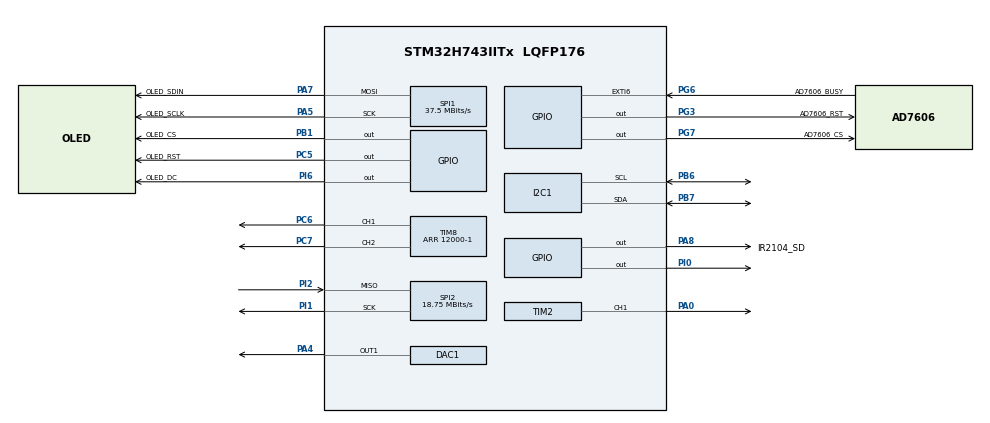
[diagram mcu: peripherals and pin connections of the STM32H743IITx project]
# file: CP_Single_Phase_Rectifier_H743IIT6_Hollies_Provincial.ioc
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ADC3.Channel-1\#ChannelRegularConversion=ADC_CHANNEL_TEMPSENSOR
ADC3.ClockPrescalerADC3=ADC_CLOCK_ASYNC_DIV2
ADC3.NbrOfConversion=1
ADC3.NbrOfConversionFlag=1
ADC3.OffsetNumber-1\#ChannelRegularConversion=ADC_OFFSET_NONE
ADC3.OffsetSignedSaturation-1\#ChannelRegularConversion=DISABLE
ADC3.Overrun=ADC_OVR_DATA_OVERWRITTEN
ADC3.OversamplingMode=ENABLE
ADC3.Rank-1\#ChannelRegularConversion=1
ADC3.Ratio=15
ADC3.RightBitShift=ADC_RIGHTBITSHIFT_4
ADC3.SamplingTime-1\#ChannelRegularConversion=ADC_SAMPLETIME_810CYCLES_5
CORTEX_M7.AccessPermission_Spec=MPU_REGION_FULL_ACCESS
CORTEX_M7.BaseAddress_Spec=0x24000000
CORTEX_M7.CPU_DCache=Enabled
CORTEX_M7.CPU_ICache=Enabled
CORTEX_M7.DisableExec_Spec=MPU_INSTRUCTION_ACCESS_ENABLE
CORTEX_M7.IsBufferable_Spec=MPU_ACCESS_BUFFERABLE
CORTEX_M7.IsCacheable_Spec=MPU_ACCESS_CACHEABLE
CORTEX_M7.IsShareable_Spec=MPU_ACCESS_NOT_SHAREABLE
CORTEX_M7.Size_Spec=MPU_REGION_SIZE_512KB
CORTEX_M7.SubRegionDisable_Spec=0x0
CORTEX_M7.TypeExtField_Spec=MPU_TEX_LEVEL1
CORTEX_M7.default_mode_Activation=1
DAC1.DAC_Channel-DAC_OUT1=DAC_CHANNEL_1
FREERTOS.Tasks01=stateLED,24,256,StartStateLED,As weak,NULL,Dynamic,NULL,NULL;mcuTemperature,24,512,StartMcuTemperature,As weak,NULL,Dynamic,NULL,NULL;oledDisplay,40,512,StartOledDisplay,As weak,NULL,Dynamic,NULL,NULL;dcSampling,40,512,StartDCSampling,As weak,NULL,Dynamic,NULL,NULL;circuitProtecti,40,512,StartCircuitProtection,As weak,NULL,Dynamic,NULL,NULL;dcControl,40,256,StartDCControl,As weak,NULL,Dynamic,NULL,NULL
I2C1.Timing=0x307075B1
Mcu.Family=STM32H7
Mcu.Name=STM32H743IITx
Mcu.Package=LQFP176
NVIC.EXTI9_5_IRQn=true\:4\:0\:true\:false\:true\:false\:true\:true\:true
NVIC.PriorityGroup=NVIC_PRIORITYGROUP_4
NVIC.TIM6_DAC_IRQn=true\:5\:0\:false\:false\:true\:false\:false\:true\:true
NVIC.TimeBase=TIM6_DAC_IRQn
NVIC.TimeBaseIP=TIM6
PA0.GPIO_Speed=GPIO_SPEED_FREQ_HIGH
PA0.Signal=S_TIM2_CH1_ETR
PA13\ (JTMS/SWDIO).Mode=Serial_Wire
PA13\ (JTMS/SWDIO).Signal=DEBUG_JTMS-SWDIO
PA14\ (JTCK/SWCLK).Mode=Serial_Wire
PA14\ (JTCK/SWCLK).Signal=DEBUG_JTCK-SWCLK
PA4.Signal=COMP_DAC11_group
PA5.GPIO_Label=OLED_SCLK
PA5.GPIO_Speed=GPIO_SPEED_FREQ_MEDIUM
PA5.Mode=TX_Only_Simplex_Unidirect_Master
PA5.Signal=SPI1_SCK
PA7.GPIO_Label=OLED_SDIN
PA7.GPIO_Speed=GPIO_SPEED_FREQ_MEDIUM
PA7.Mode=TX_Only_Simplex_Unidirect_Master
PA7.Signal=SPI1_MOSI
PA8.GPIO_Label=IR2104_SD
PA8.GPIO_PuPd=GPIO_PULLDOWN
PA8.Signal=GPIO_Output
PB1.GPIO_Label=OLED_CS
PB1.GPIO_Speed=GPIO_SPEED_FREQ_MEDIUM
PB1.Signal=GPIO_Output
PB6.GPIO_Speed=GPIO_SPEED_FREQ_MEDIUM
PB6.Mode=I2C
PB6.Signal=I2C1_SCL
PB7.GPIO_Speed=GPIO_SPEED_FREQ_MEDIUM
PB7.Mode=I2C
PB7.Signal=I2C1_SDA
PC14-OSC32_IN\ (OSC32_IN).Mode=LSE-External-Oscillator
PC14-OSC32_IN\ (OSC32_IN).Signal=RCC_OSC32_IN
PC15-OSC32_OUT\ (OSC32_OUT).Mode=LSE-External-Oscillator
PC15-OSC32_OUT\ (OSC32_OUT).Signal=RCC_OSC32_OUT
PC5.GPIO_Label=OLED_RST
PC5.GPIO_Speed=GPIO_SPEED_FREQ_MEDIUM
PC5.Signal=GPIO_Output
PC6.GPIO_Speed=GPIO_SPEED_FREQ_HIGH
PC6.Signal=S_TIM8_CH1
PC7.GPIO_Speed=GPIO_SPEED_FREQ_HIGH
PC7.Signal=S_TIM8_CH2
PG3.GPIO_Label=AD7606_RST
PG3.Signal=GPIO_Output
PG6.GPIO_Label=AD7606_BUSY
PG6.GPIO_ModeDefaultEXTI=GPIO_MODE_IT_FALLING
PG6.GPIO_PuPd=GPIO_PULLUP
PG6.Signal=GPXTI6
PG7.GPIO_Label=AD7606_CS
PG7.Signal=GPIO_Output
PH0-OSC_IN\ (PH0).Mode=HSE-External-Oscillator
PH0-OSC_IN\ (PH0).Signal=RCC_OSC_IN
PH1-OSC_OUT\ (PH1).Mode=HSE-External-Oscillator
PH1-OSC_OUT\ (PH1).Signal=RCC_OSC_OUT
PI0.Signal=GPIO_Output
PI1.GPIO_Speed=GPIO_SPEED_FREQ_MEDIUM
PI1.Mode=RX_Only_Simplex_Unidirect_Master
PI1.Signal=SPI2_SCK
PI2.GPIO_Speed=GPIO_SPEED_FREQ_MEDIUM
PI2.Mode=RX_Only_Simplex_Unidirect_Master
PI2.Signal=SPI2_MISO
PI6.GPIO_Label=OLED_DC
PI6.GPIO_Speed=GPIO_SPEED_FREQ_MEDIUM
PI6.Signal=GPIO_Output
ProjectManager.HeapSize=0x2000
ProjectManager.StackSize=0x4000
ProjectManager.TargetToolchain=CMake
RCC.ADCFreq_Value=72000000
RCC.APB1Freq_Value=120000000
RCC.APB2Freq_Value=120000000
RCC.APB3Freq_Value=120000000
RCC.APB4Freq_Value=120000000
RCC.CortexFreq_Value=480000000
RCC.D1PPRE=RCC_APB3_DIV2
RCC.D2PPRE1=RCC_APB1_DIV2
RCC.D2PPRE2=RCC_APB2_DIV2
RCC.D3PPRE=RCC_APB4_DIV2
RCC.DIVM1=5
RCC.DIVM2=25
RCC.DIVM3=25
RCC.DIVN1=192
RCC.DIVN2=504
RCC.DIVN3=300
RCC.DIVP2=7
RCC.DIVQ1=20
RCC.HCLKFreq_Value=240000000
RCC.HPRE=RCC_HCLK_DIV2
RCC.HSE_VALUE=25000000
RCC.PLL2FRACN=0
RCC.PLL3FRACN=0
RCC.PLLFRACN=0
RCC.PLLSourceVirtual=RCC_PLLSOURCE_HSE
RCC.SPI123CLockSelection=RCC_SPI123CLKSOURCE_PLL3
RCC.SYSCLKFreq_VALUE=480000000
RCC.SYSCLKSource=RCC_SYSCLKSOURCE_PLLCLK
RCC.USBFreq_Value=48000000
SH.COMP_DAC11_group.0=DAC1_OUT1,DAC_OUT1
SH.S_TIM2_CH1_ETR.0=TIM2_CH1,PWM Generation1 CH1
SH.S_TIM8_CH1.0=TIM8_CH1,PWM Generation1 CH1
SH.S_TIM8_CH2.0=TIM8_CH2,PWM Generation2 CH2
SPI1.BaudRatePrescaler=SPI_BAUDRATEPRESCALER_4
SPI1.CalculateBaudRate=37.5 MBits/s
SPI1.DataSize=SPI_DATASIZE_8BIT
SPI1.Direction=SPI_DIRECTION_2LINES_TXONLY
SPI1.Mode=SPI_MODE_MASTER
SPI1.VirtualType=VM_MASTER
SPI2.BaudRatePrescaler=SPI_BAUDRATEPRESCALER_8
SPI2.CLKPolarity=SPI_POLARITY_HIGH
SPI2.CalculateBaudRate=18.75 MBits/s
SPI2.DataSize=SPI_DATASIZE_16BIT
SPI2.Direction=SPI_DIRECTION_2LINES_RXONLY
SPI2.Mode=SPI_MODE_MASTER
SPI2.VirtualType=VM_MASTER
TIM2.Channel-PWM\ Generation1\ CH1=TIM_CHANNEL_1
TIM2.OCFastMode_PWM-PWM\ Generation1\ CH1=TIM_OCFAST_ENABLE
TIM2.Period=12000-1
TIM2.Pulse-PWM\ Generation1\ CH1=9000-1
TIM8.Channel-PWM\ Generation1\ CH1=TIM_CHANNEL_1
TIM8.Channel-PWM\ Generation2\ CH2=TIM_CHANNEL_2
TIM8.OCFastMode_PWM-PWM\ Generation1\ CH1=TIM_OCFAST_ENABLE
TIM8.OCFastMode_PWM-PWM\ Generation2\ CH2=TIM_OCFAST_ENABLE
TIM8.Period=12000-1
VP_ADC3_TempSens_Input.Mode=IN-TempSens
VP_FREERTOS_VS_CMSIS_V2.Mode=CMSIS_V2
VP_MEMORYMAP_VS_MEMORYMAP.Mode=CurAppReg
VP_SYS_VS_tim6.Mode=TIM6
VP_TIM2_VS_ClockSourceINT.Mode=Internal
VP_TIM8_VS_ClockSourceINT.Mode=Internal
board=custom

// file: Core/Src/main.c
/* USER CODE BEGIN Header */
/**
  ******************************************************************************
  * @file           : main.c
  * @brief          : Main program body
  ******************************************************************************
  * @attention
  *
  * Copyright (c) 2024 STMicroelectronics.
  * All rights reserved.
  *
  * This software is licensed under terms that can be found in the LICENSE file
  * in the root directory of this software component.
  * If no LICENSE file comes with this software, it is provided AS-IS.
  *
  ******************************************************************************
  */
/* USER CODE END Header */
#include "main.h"
#include "cmsis_os.h"
#include "adc.h"
#include "dac.h"
#include "i2c.h"
#include "memorymap.h"
#include "spi.h"
#include "tim.h"
#include "gpio.h"

void SystemClock_Config(void);
void PeriphCommonClock_Config(void);
static void MPU_Config(void);
void MX_FREERTOS_Init(void);

int main(void)
{

  /* MPU Configuration--------------------------------------------------------*/
  MPU_Config();

  /* Enable the CPU Cache */

  /* Enable I-Cache---------------------------------------------------------*/
  SCB_EnableICache();

  /* Enable D-Cache---------------------------------------------------------*/
  SCB_EnableDCache();

  /* MCU Configuration--------------------------------------------------------*/

  /* Reset of all peripherals, Initializes the Flash interface and the Systick. */
  HAL_Init();

  /* Configure the system clock */
  SystemClock_Config();

  /* Configure the peripherals common clocks */
  PeriphCommonClock_Config();

  /* Initialize all configured peripherals */
  MX_GPIO_Init();
  MX_ADC3_Init();
  MX_SPI1_Init();
  MX_SPI2_Init();
  MX_I2C1_Init();
  MX_TIM2_Init();
  MX_DAC1_Init();
  MX_TIM8_Init();

  /* Init scheduler */
  osKernelInitialize();

  /* Call init function for freertos objects (in cmsis_os2.c) */
  MX_FREERTOS_Init();

  /* Start scheduler */
  osKernelStart();

  /* We should never get here as control is now taken by the scheduler */

  /* Infinite loop */
  while (1)
  {

  }
}

void SystemClock_Config(void)
{
  RCC_OscInitTypeDef RCC_OscInitStruct = {0};
  RCC_ClkInitTypeDef RCC_ClkInitStruct = {0};

  /** Supply configuration update enable
  */
  HAL_PWREx_ConfigSupply(PWR_LDO_SUPPLY);

  /** Configure the main internal regulator output voltage
  */
  __HAL_PWR_VOLTAGESCALING_CONFIG(PWR_REGULATOR_VOLTAGE_SCALE1);

  while(!__HAL_PWR_GET_FLAG(PWR_FLAG_VOSRDY)) {}

  __HAL_RCC_SYSCFG_CLK_ENABLE();
  __HAL_PWR_VOLTAGESCALING_CONFIG(PWR_REGULATOR_VOLTAGE_SCALE0);

  while(!__HAL_PWR_GET_FLAG(PWR_FLAG_VOSRDY)) {}

  /** Initializes the RCC Oscillators according to the specified parameters
  * in the RCC_OscInitTypeDef structure.
  */
  RCC_OscInitStruct.OscillatorType = RCC_OSCILLATORTYPE_HSE;
  RCC_OscInitStruct.HSEState = RCC_HSE_ON;
  RCC_OscInitStruct.PLL.PLLState = RCC_PLL_ON;
  RCC_OscInitStruct.PLL.PLLSource = RCC_PLLSOURCE_HSE;
  RCC_OscInitStruct.PLL.PLLM = 5;
  RCC_OscInitStruct.PLL.PLLN = 192;
  RCC_OscInitStruct.PLL.PLLP = 2;
  RCC_OscInitStruct.PLL.PLLQ = 20;
  RCC_OscInitStruct.PLL.PLLR = 2;
  RCC_OscInitStruct.PLL.PLLRGE = RCC_PLL1VCIRANGE_2;
  RCC_OscInitStruct.PLL.PLLVCOSEL = RCC_PLL1VCOWIDE;
  RCC_OscInitStruct.PLL.PLLFRACN = 0;
  if (HAL_RCC_OscConfig(&RCC_OscInitStruct) != HAL_OK)
  {
    Error_Handler();
  }

  /** Initializes the CPU, AHB and APB buses clocks
  */
  RCC_ClkInitStruct.ClockType = RCC_CLOCKTYPE_HCLK|RCC_CLOCKTYPE_SYSCLK
                              |RCC_CLOCKTYPE_PCLK1|RCC_CLOCKTYPE_PCLK2
                              |RCC_CLOCKTYPE_D3PCLK1|RCC_CLOCKTYPE_D1PCLK1;
  RCC_ClkInitStruct.SYSCLKSource = RCC_SYSCLKSOURCE_PLLCLK;
  RCC_ClkInitStruct.SYSCLKDivider = RCC_SYSCLK_DIV1;
  RCC_ClkInitStruct.AHBCLKDivider = RCC_HCLK_DIV2;
  RCC_ClkInitStruct.APB3CLKDivider = RCC_APB3_DIV2;
  RCC_ClkInitStruct.APB1CLKDivider = RCC_APB1_DIV2;
  RCC_ClkInitStruct.APB2CLKDivider = RCC_APB2_DIV2;
  RCC_ClkInitStruct.APB4CLKDivider = RCC_APB4_DIV2;

  if (HAL_RCC_ClockConfig(&RCC_ClkInitStruct, FLASH_LATENCY_4) != HAL_OK)
  {
    Error_Handler();
  }
}

void PeriphCommonClock_Config(void)
{
  RCC_PeriphCLKInitTypeDef PeriphClkInitStruct = {0};

  /** Initializes the peripherals clock
  */
  PeriphClkInitStruct.PeriphClockSelection = RCC_PERIPHCLK_SPI2|RCC_PERIPHCLK_SPI1;
  PeriphClkInitStruct.PLL3.PLL3M = 25;
  PeriphClkInitStruct.PLL3.PLL3N = 300;
  PeriphClkInitStruct.PLL3.PLL3P = 2;
  PeriphClkInitStruct.PLL3.PLL3Q = 2;
  PeriphClkInitStruct.PLL3.PLL3R = 2;
  PeriphClkInitStruct.PLL3.PLL3RGE = RCC_PLL3VCIRANGE_0;
  PeriphClkInitStruct.PLL3.PLL3VCOSEL = RCC_PLL3VCOWIDE;
  PeriphClkInitStruct.PLL3.PLL3FRACN = 0;
  PeriphClkInitStruct.Spi123ClockSelection = RCC_SPI123CLKSOURCE_PLL3;
  if (HAL_RCCEx_PeriphCLKConfig(&PeriphClkInitStruct) != HAL_OK)
  {
    Error_Handler();
  }
}

 /* MPU Configuration */

void MPU_Config(void)
{
  MPU_Region_InitTypeDef MPU_InitStruct = {0};

  /* Disables the MPU */
  HAL_MPU_Disable();

  /** Initializes and configures the Region and the memory to be protected
  */
  MPU_InitStruct.Enable = MPU_REGION_ENABLE;
  MPU_InitStruct.Number = MPU_REGION_NUMBER0;
  MPU_InitStruct.BaseAddress = 0x24000000;
  MPU_InitStruct.Size = MPU_REGION_SIZE_512KB;
  MPU_InitStruct.SubRegionDisable = 0x0;
  MPU_InitStruct.TypeExtField = MPU_TEX_LEVEL1;
  MPU_InitStruct.AccessPermission = MPU_REGION_FULL_ACCESS;
  MPU_InitStruct.DisableExec = MPU_INSTRUCTION_ACCESS_ENABLE;
  MPU_InitStruct.IsShareable = MPU_ACCESS_NOT_SHAREABLE;
  MPU_InitStruct.IsCacheable = MPU_ACCESS_CACHEABLE;
  MPU_InitStruct.IsBufferable = MPU_ACCESS_BUFFERABLE;

  HAL_MPU_ConfigRegion(&MPU_InitStruct);
  /* Enables the MPU */
  HAL_MPU_Enable(MPU_PRIVILEGED_DEFAULT);

}

void HAL_TIM_PeriodElapsedCallback(TIM_HandleTypeDef *htim)
{
  if (htim->Instance == TIM6) {
    HAL_IncTick();
  }
}

void Error_Handler(void)
{
  __disable_irq();
  while (1)
  {
  }
}

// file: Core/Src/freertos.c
/* USER CODE BEGIN Header */
/**
 ******************************************************************************
 * File Name          : freertos.c
 * Description        : Code for freertos applications
 ******************************************************************************
 * @attention
 *
 * Copyright (c) 2024 STMicroelectronics.
 * All rights reserved.
 *
 * This software is licensed under terms that can be found in the LICENSE file
 * in the root directory of this software component.
 * If no LICENSE file comes with this software, it is provided AS-IS.
 *
 ******************************************************************************
 */
/* USER CODE END Header */

#include "FreeRTOS.h"
#include "task.h"
#include "main.h"
#include "cmsis_os.h"

/* USER CODE BEGIN Includes */
#include "user_task.h"
/* USER CODE END Includes */

/* Definitions for stateLED */
osThreadId_t stateLEDHandle;
const osThreadAttr_t stateLED_attributes = {
  .name = "stateLED",
  .stack_size = 256 * 4,
  .priority = (osPriority_t) osPriorityNormal,
};
/* Definitions for mcuTemperature */
osThreadId_t mcuTemperatureHandle;
const osThreadAttr_t mcuTemperature_attributes = {
  .name = "mcuTemperature",
  .stack_size = 512 * 4,
  .priority = (osPriority_t) osPriorityNormal,
};
/* Definitions for oledDisplay */
osThreadId_t oledDisplayHandle;
const osThreadAttr_t oledDisplay_attributes = {
  .name = "oledDisplay",
  .stack_size = 512 * 4,
  .priority = (osPriority_t) osPriorityHigh,
};
/* Definitions for dcSampling */
osThreadId_t dcSamplingHandle;
const osThreadAttr_t dcSampling_attributes = {
  .name = "dcSampling",
  .stack_size = 512 * 4,
  .priority = (osPriority_t) osPriorityHigh,
};
/* Definitions for circuitProtecti */
osThreadId_t circuitProtectiHandle;
const osThreadAttr_t circuitProtecti_attributes = {
  .name = "circuitProtecti",
  .stack_size = 512 * 4,
  .priority = (osPriority_t) osPriorityHigh,
};
/* Definitions for dcControl */
osThreadId_t dcControlHandle;
const osThreadAttr_t dcControl_attributes = {
  .name = "dcControl",
  .stack_size = 256 * 4,
  .priority = (osPriority_t) osPriorityHigh,
};

void StartStateLED(void *argument);
void StartMcuTemperature(void *argument);
void StartOledDisplay(void *argument);
void StartDCSampling(void *argument);
void StartCircuitProtection(void *argument);
void StartDCControl(void *argument);

void MX_FREERTOS_Init(void); /* (MISRA C 2004 rule 8.1) */

void MX_FREERTOS_Init(void) {
  /* USER CODE BEGIN Init */
  UserInit();
  /* USER CODE END Init */

  /* Create the thread(s) */
  /* creation of stateLED */
  stateLEDHandle = osThreadNew(StartStateLED, NULL, &stateLED_attributes);

  /* creation of mcuTemperature */
  mcuTemperatureHandle = osThreadNew(StartMcuTemperature, NULL, &mcuTemperature_attributes);

  /* creation of oledDisplay */
  oledDisplayHandle = osThreadNew(StartOledDisplay, NULL, &oledDisplay_attributes);

  /* creation of dcSampling */
  dcSamplingHandle = osThreadNew(StartDCSampling, NULL, &dcSampling_attributes);

  /* creation of circuitProtecti */
  circuitProtectiHandle = osThreadNew(StartCircuitProtection, NULL, &circuitProtecti_attributes);

  /* creation of dcControl */
  dcControlHandle = osThreadNew(StartDCControl, NULL, &dcControl_attributes);

}

__weak void StartStateLED(void *argument)
{
  /* USER CODE BEGIN StartStateLED */
  UNUSED(argument);
  /* Infinite loop */
  for (;;)
  {
    osDelay(1);
  }
  /* USER CODE END StartStateLED */
}

__weak void StartMcuTemperature(void *argument)
{
  /* USER CODE BEGIN StartMcuTemperature */
  UNUSED(argument);
  /* Infinite loop */
  for (;;)
  {
    osDelay(1);
  }
  /* USER CODE END StartMcuTemperature */
}

__weak void StartOledDisplay(void *argument)
{
  /* USER CODE BEGIN StartOledDisplay */
  UNUSED(argument);
  /* Infinite loop */
  for (;;)
  {
    osDelay(1);
  }
  /* USER CODE END StartOledDisplay */
}

__weak void StartDCSampling(void *argument)
{
  /* USER CODE BEGIN StartDCSampling */
  UNUSED(argument);
  /* Infinite loop */
  for (;;)
  {
    osDelay(1);
  }
  /* USER CODE END StartDCSampling */
}

__weak void StartCircuitProtection(void *argument)
{
  /* USER CODE BEGIN StartCircuitProtection */
  UNUSED(argument);
  /* Infinite loop */
  for (;;)
  {
    osDelay(1);
  }
  /* USER CODE END StartCircuitProtection */
}

__weak void StartDCControl(void *argument)
{
  /* USER CODE BEGIN StartDCControl */
  UNUSED(argument);
  /* Infinite loop */
  for (;;)
  {
    osDelay(1);
  }
  /* USER CODE END StartDCControl */
}
